# iND83213A register map
Vendor: Indiemicro; Series: Rugby; File version: 1.0
CPU: CM0 r0p1, selectable endian, no MPU, no FPU, 4 interrupt priority bits
Registers are 32-bit, read-write, no defined reset value unless marked. A register's access mark holds for its fields unless they carry their own. Offsets are from the block's base; [hi:lo] are bit positions; <NAME> marks a mode.

## IOCTRLA — I/O configuration and DFT pin control
Base 0x50012000; register names take the prefix IOCTRLA_
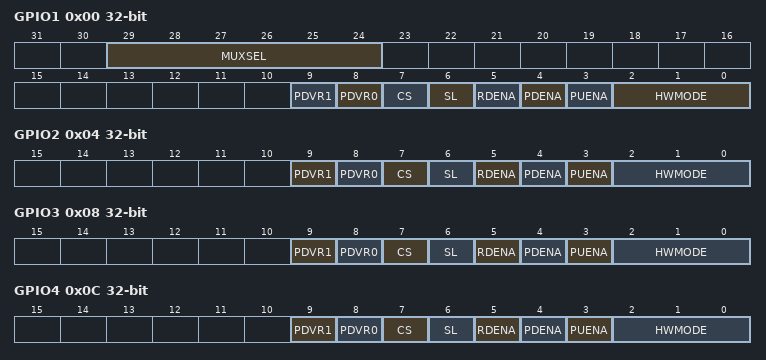
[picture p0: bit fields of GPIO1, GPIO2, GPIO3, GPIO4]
0x00 GPIO1 — GPIO Pin 1 Control
  [29:24] MUXSEL — Selects debug signal to be output on gpio1. 0x0: PMUA (Power Management Unit Asic) qacks[0] 0x1: PMUA (Power Management Unit Asic) daffodil[0] 0x2: PMUA (Power Management Unit Asic) snowflake[0] 0x3: CRGA (Clock Reset Generation Asic) lf_rc_clk 0x4: CRGA (Clock Reset Generation Asic) hf_rc_clk 0x5: CRGA (Clock Reset Generation Asic) lf_rc_sts 0x6: CRGA (Clock Reset Generation Asic) hf_rc_sts 0x7: CRGA (Clock Reset Generation Asic) clk_sys_gated 0x8: CRGA (Clock Reset Generation Asic) (a_por_n) 0x9: CRGA (Clock Reset Generation Asic) (bor_3v3_n) 0xa: CRGA (Clock Reset Generation Asic) (ovtemp_flag) 0xb: CRGA (Clock Reset Generation Asic) (bor_1v5_n) 0xc: CRGA (Clock Reset Generation Asic) (wdt_bark) 0xd: Reserved 0xe: ADC ctrl (Analog to Digital Converter Controller) adc_done 0xf: ADC ctrl (Analog to Digital Converter Controller) sar_dout 0x10: ADC ctrl (Analog to Digital Converter Controller) sar_smp_vcm 0x11: ADC ctrl (Analog to Digital Converter Controller) sar_div_clk 0x12: LINM Controller rxd 0x13: LINM Controller txd 0x14: LINS Controller rxd 0x15: LINS Controller txd 0x16: BOR CONTROL STATE MACHINE state[0] 0x17: BOR CONTROL STATE MACHINE state[1] 0x18: BOR CONTROL STATE MACHINE bor_bias_ena 0x19: BOR CONTROL STATE MACHINE bor_bias_ena_l 0x1a: BOR CONTROL STATE MACHINE pmua_bor_bias_ena 0x1b: BOR CONTROL STATE MACHINE hf_clk_allowed 0x1c: BOR CONTROL STATE MACHINE hf_active 0x1d: BOR CONTROL STATE MACHINE pmua_bor_arm_sync 0x1e: BATTERY VOLTAGE MONITOR raw output from vbat low comp 0x1f: BATTERY VOLTAGE MONITOR raw output from vbat high comp 0x20: BATTERY VOLTAGE MONITOR synchronised vbat low signal with polarity adjusted 0x21: BATTERY VOLTAGE MONITOR synchronised vbat high signal with polarity adjusted 0x22: BATTERY VOLTAGE MONITOR debounced synchronised vbat low signal 0x23: BATTERY VOLTAGE MONITOR debounced synchronised vbat high signal 0x24: BUCK dtb[0] 0x25: BUCK dtb[1] 0x26: Output of LINS 1st Stage Glitch Filter 0x27: Output of LINS 2nd Stage Glitch Filter 0x28: Output of LINS 3rd Stage Glitch Filter 0x29: Input of LINS 1st Stage Glitch Filter 0x2a: LINS PHY TXD 0x2b: Output of LINM 1st Stage Glitch Filter 0x2c: Output of LINM 2nd Stage Glitch Filter 0x2d: Output of LINM 3rd Stage Glitch Filter 0x2e: Input of LINM 1st Stage Glitch Filter 0x2f: LINM PHY TXD
  [9] PDVR1 — GPIO output drive strength MSB selector. GPIO output drive strength MSB selector. <table id="indie_table_table_regs"> <tbody><tr> <td> PDRV1 </td> <td> PDRV0 </td> <td> Output drive strength </td> </tr> <tr> <td> 0 </td> <td> 0 </td> <td> 4mA </td> </tr> <tr> <td> 0 </td> <td> 1 </td> <td> 8mA </td> </tr> <tr> <td> 1 </td> <td> 0 </td> <td> 12mA </td> </tr> <tr> <td> 1 </td> <td> 1 </td> <td> 16mA </td> </tr></tbody></table>
  [8] PDVR0 — GPIO output drive strength LSB selector. GPIO output drive strength LSB selector.
  [7] CS — input schmitt trigger enable. 0x0: Disable schmitt trigger 0x1: Enable schmitt trigger.
  [6] SL — slewrate ctrl. 0x0: Fast Slewrate on the GPIO 0x1: Slow Slewrate on the GPIO
  [5] RDENA — read enable. 0x0: Disable Read path on the GPIO 0x1: Enable Read path on the GPIO
  [4] PDENA — pulldown enable. 0x0: Disable 100K Ohm Pull Down 0x1: Enable 100K Ohm Pull Down
  [3] PUENA — pullup enable (active-low). 0x0: Enable 100K Ohm Pull Up 0x1: Disable 100K Ohm Pull Up
  [2:0] HWMODE — hardware mode. 0x0: GPA[0] Mode. 'GPIO Barium' reads and writes data to the GPIO. Output Enable is controlled by GPIO Barium via the direction bit. Read Enable, Pull-Up, and Pull-Down are controlled by GPIO register in IOCTRLA. 0x1: PWM[0] Mode. 'PWM Barium' writes data to the GPIO. 0x2: Testmux Mode. 'Digital Testmux' writes data to the GPIO. DEBUG Access must be enabled in the system control block to allow testmux outputs. 0x3: LINM controller RXD Input from GPIO(External PHY). 0x4: LINM Single wire mode, LINM PHY RXD/LINM PHY TXD, Open-drain output. 0x5: Output of LINS 3rd Stage Glitch Filter. 0x6: Output of LINM 3rd Stage Glitch Filter.
0x04 GPIO2 — GPIO Pin 2 Control
  [9] PDVR1 — GPIO output drive strength MSB selector. GPIO output drive strength MSB selector. <table id="indie_table_table_regs"> <tbody><tr> <td> PDRV1 </td> <td> PDRV0 </td> <td> Output drive strength </td> </tr> <tr> <td> 0 </td> <td> 0 </td> <td> 4mA </td> </tr> <tr> <td> 0 </td> <td> 1 </td> <td> 8mA </td> </tr> <tr> <td> 1 </td> <td> 0 </td> <td> 12mA </td> </tr> <tr> <td> 1 </td> <td> 1 </td> <td> 16mA </td> </tr></tbody></table>
  [8] PDVR0 — GPIO output drive strength LSB selector. GPIO output drive strength LSB selector.
  [7] CS — input schmitt trigger enable. 0x0: Disable schmitt trigger 0x1: Enable schmitt trigger.
  [6] SL — slewrate ctrl. 0x0: Fast Slewrate on the GPIO 0x1: Slow Slewrate on the GPIO
  [5] RDENA — read enable. 0x0: Disable Read path on the GPIO 0x1: Enable Read path on the GPIO
  [4] PDENA — pulldown enable. 0x0: Disable 100K Ohm Pull Down 0x1: Enable 100K Ohm Pull Down
  [3] PUENA — pullup enable (active-low). 0x0: Enable 100K Ohm Pull Up 0x1: Disable 100K Ohm Pull Up
  [2:0] HWMODE — hardware mode. 0x0: GPA[1] Mode. 'GPIO Barium' reads and writes data to the GPIO. Output Enable is controlled by GPIO Barium via the direction bit. Read Enable, Pull-Up, and Pull-Down are controlled by GPIO register in IOCTRLA. 0x1: PWM[1] Mode. 'PWM Barium' writes data to the GPIO. 0x2: Testmux Mode. GPIO input connects to LINS PHY TXD. DEBUG Access must be enabled in the system control block to allow testmux outputs. 0x3: LINM PHY TXD. 0x4: SPI Master Slave Select. 0x5: bor_3v3_n, BOR 3V3 reset. 0x6: bor_1v5_n, BOR 1V5 reset. 0x7: Input of LINS 1st Stage Glitch Filter.
0x08 GPIO3 — GPIO Pin 3 Control
  [9] PDVR1 — GPIO output drive strength MSB selector. GPIO output drive strength MSB selector. <table id="indie_table_table_regs"> <tbody><tr> <td> PDRV1 </td> <td> PDRV0 </td> <td> Output drive strength </td> </tr> <tr> <td> 0 </td> <td> 0 </td> <td> 4mA </td> </tr> <tr> <td> 0 </td> <td> 1 </td> <td> 8mA </td> </tr> <tr> <td> 1 </td> <td> 0 </td> <td> 12mA </td> </tr> <tr> <td> 1 </td> <td> 1 </td> <td> 16mA </td> </tr></tbody></table>
  [8] PDVR0 — GPIO output drive strength LSB selector. GPIO output drive strength LSB selector.
  [7] CS — input schmitt trigger enable. 0x0: Disable schmitt trigger 0x1: Enable schmitt trigger.
  [6] SL — slewrate ctrl. 0x0: Fast Slewrate on the GPIO 0x1: Slow Slewrate on the GPIO
  [5] RDENA — read enable. 0x0: Disable Read path on the GPIO 0x1: Enable Read path on the GPIO
  [4] PDENA — pulldown enable. 0x0: Disable 100K Ohm Pull Down 0x1: Enable 100K Ohm Pull Down
  [3] PUENA — pullup enable (active-low). 0x0: Enable 100K Ohm Pull Up 0x1: Disable 100K Ohm Pull Up
  [2:0] HWMODE — hardware mode. 0x0: GPA[2] Mode. 'GPIO Barium' reads and writes data to the GPIO. Output Enable is controlled by GPIO Barium via the direction bit. Read Enable, Pull-Up, and Pull-Down are controlled by GPIO register in IOCTRLA. 0x1: PWM[2] Mode. 'PWM Barium' writes data to the GPIO. 0x2: LINM controller RXD connects to GPIO for observe. 0x3: LINS controller RXD Input from GPIO(External PHY). 0x4: LINS Single wire mode, LINS PHY RXD/LINS PHY TXD, Open-drain output. 0x5: SPI Master Clock Out. 0x6: Output of LINS 1st Stage Glitch Filter. 0x7: Output of LINM 1st Stage Glitch Filter.
0x0C GPIO4 — GPIO Pin 4 Control
  [9] PDVR1 — GPIO output drive strength MSB selector. GPIO output drive strength MSB selector. <table id="indie_table_table_regs"> <tbody><tr> <td> PDRV1 </td> <td> PDRV0 </td> <td> Output drive strength </td> </tr> <tr> <td> 0 </td> <td> 0 </td> <td> 4mA </td> </tr> <tr> <td> 0 </td> <td> 1 </td> <td> 8mA </td> </tr> <tr> <td> 1 </td> <td> 0 </td> <td> 12mA </td> </tr> <tr> <td> 1 </td> <td> 1 </td> <td> 16mA </td> </tr></tbody></table>
  [8] PDVR0 — GPIO output drive strength LSB selector. GPIO output drive strength LSB selector.
  [7] CS — input schmitt trigger enable. 0x0: Disable schmitt trigger 0x1: Enable schmitt trigger.
  [6] SL — slewrate ctrl. 0x0: Fast Slewrate on the GPIO 0x1: Slow Slewrate on the GPIO
  [5] RDENA — read enable. 0x0: Disable Read path on the GPIO 0x1: Enable Read path on the GPIO
  [4] PDENA — pulldown enable. 0x0: Disable 100K Ohm Pull Down 0x1: Enable 100K Ohm Pull Down
  [3] PUENA — pullup enable (active-low). 0x0: Enable 100K Ohm Pull Up 0x1: Disable 100K Ohm Pull Up
  [2:0] HWMODE — hardware mode. 0x0: GPA[3] Mode. 'GPIO Barium' reads and writes data to the GPIO. Output Enable is controlled by GPIO Barium via the direction bit. Read Enable, Pull-Up, and Pull-Down are controlled by GPIO register in IOCTRLA. 0x1: PWM[3] Mode. 'PWM Barium' writes data to the GPIO. 0x2: UART RXD Input from GPIO 0x3: UART Single Wire Mode 0x4: SPI Master MOSI 0x5: Testmux Mode. GPIO input connects to LINM PHY TXD. 0x6: Output of LINS 2nd Stage Glitch Filter. 0x7: Output of LINM 2nd Stage Glitch Filter.
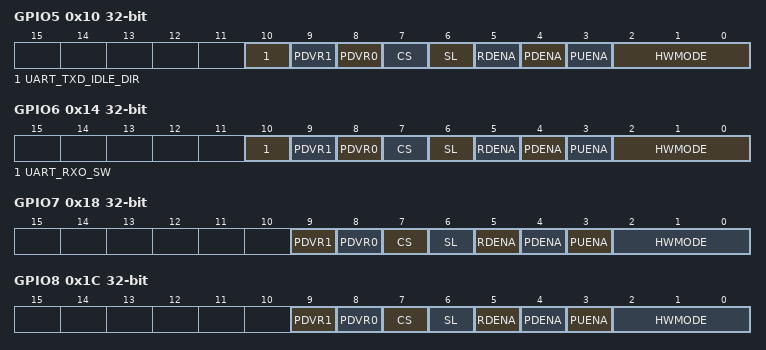
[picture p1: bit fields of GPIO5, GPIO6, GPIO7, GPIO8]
0x10 GPIO5 — GPIO Pin 5 Control
  [10] UART_TXD_IDLE_DIR — Control the direction of PAD for UART TXD Idle. 0x0: Hold the UART TXD Pad to output when TXD is idle, 0x1: Switch the TXD Pad to input When TXD is idle.
  [9] PDVR1 — GPIO output drive strength MSB selector. GPIO output drive strength MSB selector. <table id="indie_table_table_regs"> <tbody><tr> <td> PDRV1 </td> <td> PDRV0 </td> <td> Output drive strength </td> </tr> <tr> <td> 0 </td> <td> 0 </td> <td> 4mA </td> </tr> <tr> <td> 0 </td> <td> 1 </td> <td> 8mA </td> </tr> <tr> <td> 1 </td> <td> 0 </td> <td> 12mA </td> </tr> <tr> <td> 1 </td> <td> 1 </td> <td> 16mA </td> </tr></tbody></table>
  [8] PDVR0 — GPIO output drive strength LSB selector. GPIO output drive strength LSB selector.
  [7] CS — input schmitt trigger enable. 0x0: Disable schmitt trigger 0x1: Enable schmitt trigger.
  [6] SL — slewrate ctrl. 0x0: Fast Slewrate on the GPIO 0x1: Slow Slewrate on the GPIO
  [5] RDENA — read enable. 0x0: Disable Read path on the GPIO 0x1: Enable Read path on the GPIO
  [4] PDENA — pulldown enable. 0x0: Disable 100K Ohm Pull Down 0x1: Enable 100K Ohm Pull Down
  [3] PUENA — pullup enable (active-low). 0x0: Enable 100K Ohm Pull Up 0x1: Disable 100K Ohm Pull Up
  [2:0] HWMODE — hardware mode. 0x0: GPA[4] Mode. 'GPIO Barium' reads and writes data to the GPIO. Output Enable is controlled by GPIO Barium via the direction bit. Read Enable, Pull-Up, and Pull-Down are controlled by GPIO register in IOCTRLA. 0x1: PWM[4] Mode. 'PWM Barium' writes data to the GPIO. 0x2: UART TXD Output to GPIO 0x3: LINS PHY TXD Output to GPIO. 0x4: SPI Master MISO. 0x5: Input of LINM 1st Stage Glitch Filter. 0x6: Output of LINS 1st Stage Glitch Filter. 0x7: Output of LINM 1st Stage Glitch Filter.
0x14 GPIO6 — GPIO Pin 6 Control
  [10] UART_RXO_SW — UART RX output Switch. 0x0: Bypass UART RXD 0x1: Force UART RXD output to Reset Value-'1'
  [9] PDVR1 — GPIO output drive strength MSB selector. GPIO output drive strength MSB selector. <table id="indie_table_table_regs"> <tbody><tr> <td> PDRV1 </td> <td> PDRV0 </td> <td> Output drive strength </td> </tr> <tr> <td> 0 </td> <td> 0 </td> <td> 4mA </td> </tr> <tr> <td> 0 </td> <td> 1 </td> <td> 8mA </td> </tr> <tr> <td> 1 </td> <td> 0 </td> <td> 12mA </td> </tr> <tr> <td> 1 </td> <td> 1 </td> <td> 16mA </td> </tr></tbody></table>
  [8] PDVR0 — GPIO output drive strength LSB selector. GPIO output drive strength LSB selector.
  [7] CS — input schmitt trigger enable. 0x0: Disable schmitt trigger 0x1: Enable schmitt trigger.
  [6] SL — slewrate ctrl. 0x0: Fast Slewrate on the GPIO 0x1: Slow Slewrate on the GPIO
  [5] RDENA — read enable. 0x0: Disable Read path on the GPIO 0x1: Enable Read path on the GPIO
  [4] PDENA — pulldown enable. 0x0: Disable 100K Ohm Pull Down 0x1: Enable 100K Ohm Pull Down
  [3] PUENA — pullup enable (active-low). 0x0: Enable 100K Ohm Pull Up 0x1: Disable 100K Ohm Pull Up
  [2:0] HWMODE — hardware mode. 0x0: GPA[5] Mode. 'GPIO Barium' reads and writes data to the GPIO. Output Enable is controlled by GPIO Barium via the direction bit. Read Enable, Pull-Up, and Pull-Down are controlled by GPIO register in IOCTRLA. 0x1: PWM[1] Mode. 'PWM Barium' writes data to the GPIO. 0x2: Testmux Mode. Output of LINS 3rd Stage Glitch Filter. 0x3: LINM controller txd or txd_timeout_dominant to GPIO. 0x4: SPI Master MISO. 0x5: UART RXD Output to GPIO. 0x6: Output of LINS 2nd Stage Glitch Filter. 0x7: Output of LINM 2nd Stage Glitch Filter.
0x18 GPIO7 — GPIO Pin 7 Control
  [9] PDVR1 — GPIO output drive strength MSB selector. GPIO output drive strength MSB selector. <table id="indie_table_table_regs"> <tbody><tr> <td> PDRV1 </td> <td> PDRV0 </td> <td> Output drive strength </td> </tr> <tr> <td> 0 </td> <td> 0 </td> <td> 4mA </td> </tr> <tr> <td> 0 </td> <td> 1 </td> <td> 8mA </td> </tr> <tr> <td> 1 </td> <td> 0 </td> <td> 12mA </td> </tr> <tr> <td> 1 </td> <td> 1 </td> <td> 16mA </td> </tr></tbody></table>
  [8] PDVR0 — GPIO output drive strength LSB selector. GPIO output drive strength LSB selector.
  [7] CS — input schmitt trigger enable. 0x0: Disable schmitt trigger 0x1: Enable schmitt trigger.
  [6] SL — slewrate ctrl. 0x0: Fast Slewrate on the GPIO 0x1: Slow Slewrate on the GPIO
  [5] RDENA — read enable. 0x0: Disable Read path on the GPIO 0x1: Enable Read path on the GPIO
  [4] PDENA — pulldown enable. 0x0: Disable 100K Ohm Pull Down 0x1: Enable 100K Ohm Pull Down
  [3] PUENA — pullup enable (active-low). 0x0: Enable 100K Ohm Pull Up 0x1: Disable 100K Ohm Pull Up
  [2:0] HWMODE — hardware mode. 0x0: GPA[6] Mode. 'GPIO Barium' reads and writes data to the GPIO. Output Enable is controlled by GPIO Barium via the direction bit. Read Enable, Pull-Up, and Pull-Down are controlled by GPIO register in IOCTRLA. 0x1: PWM[2] Mode. 'PWM Barium' writes data to the GPIO. 0x2: Testmux Mode. Output of LINM 3rd Stage Glitch Filter. 0x3: LINS RXD Input from GPIO(External PHY). 0x4: LINS Single wire mode, LINS PHY RXD/LINS PHY TXD, Open-drain output. 0x5: SPI Master Clock Out. 0x6: UART TXD Input from GPIO. 0x7: Input of LINM 1st Stage Glitch Filter.
0x1C GPIO8 — GPIO Pin 8 Control
  [9] PDVR1 — GPIO output drive strength MSB selector. GPIO output drive strength MSB selector. <table id="indie_table_table_regs"> <tbody><tr> <td> PDRV1 </td> <td> PDRV0 </td> <td> Output drive strength </td> </tr> <tr> <td> 0 </td> <td> 0 </td> <td> 4mA </td> </tr> <tr> <td> 0 </td> <td> 1 </td> <td> 8mA </td> </tr> <tr> <td> 1 </td> <td> 0 </td> <td> 12mA </td> </tr> <tr> <td> 1 </td> <td> 1 </td> <td> 16mA </td> </tr></tbody></table>
  [8] PDVR0 — GPIO output drive strength LSB selector. GPIO output drive strength LSB selector.
  [7] CS — input schmitt trigger enable. 0x0: Disable schmitt trigger 0x1: Enable schmitt trigger.
  [6] SL — slewrate ctrl. 0x0: Fast Slewrate on the GPIO 0x1: Slow Slewrate on the GPIO
  [5] RDENA — read enable. 0x0: Disable Read path on the GPIO 0x1: Enable Read path on the GPIO
  [4] PDENA — pulldown enable. 0x0: Disable 100K Ohm Pull Down 0x1: Enable 100K Ohm Pull Down
  [3] PUENA — pullup enable (active-low). 0x0: Enable 100K Ohm Pull Up 0x1: Disable 100K Ohm Pull Up
  [2:0] HWMODE — hardware mode. 0x0: GPA[7] Mode. 'GPIO Barium' reads and writes data to the GPIO. Output Enable is controlled by GPIO Barium via the direction bit. Read Enable, Pull-Up, and Pull-Down are controlled by GPIO register in IOCTRLA. 0x1: PWM[3] Mode. 'PWM Barium' writes data to the GPIO. 0x2: UART RXD Input from GPIO 0x3: UART Single Wire Mode 0x4: SPI Master MOSI 0x5: Output of LINS 2nd Stage Glitch Filter. 0x6: Output of LINM 2nd Stage Glitch Filter.
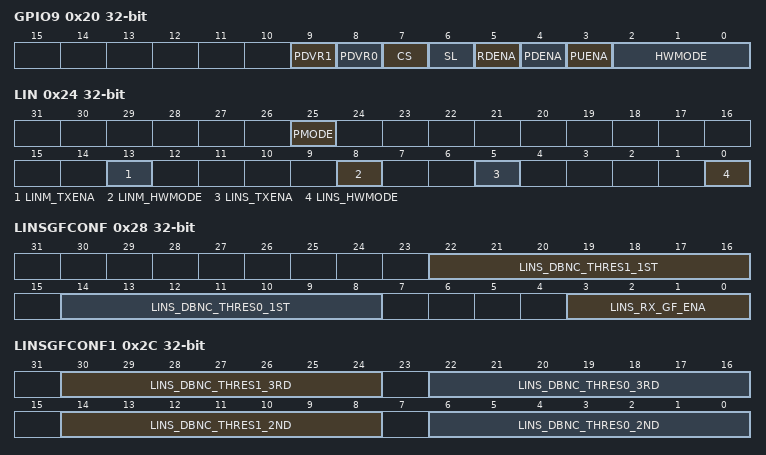
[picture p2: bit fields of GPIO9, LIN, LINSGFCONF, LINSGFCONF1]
0x20 GPIO9 — GPIO Pin 9 Control
  [9] PDVR1 — GPIO output drive strength MSB selector. GPIO output drive strength MSB selector. <table id="indie_table_table_regs"> <tbody><tr> <td> PDRV1 </td> <td> PDRV0 </td> <td> Output drive strength </td> </tr> <tr> <td> 0 </td> <td> 0 </td> <td> 4mA </td> </tr> <tr> <td> 0 </td> <td> 1 </td> <td> 8mA </td> </tr> <tr> <td> 1 </td> <td> 0 </td> <td> 12mA </td> </tr> <tr> <td> 1 </td> <td> 1 </td> <td> 16mA </td> </tr></tbody></table>
  [8] PDVR0 — GPIO output drive strength LSB selector. GPIO output drive strength LSB selector.
  [7] CS — input schmitt trigger enable. 0x0: Disable schmitt trigger 0x1: Enable schmitt trigger.
  [6] SL — slewrate ctrl. 0x0: Fast Slewrate on the GPIO 0x1: Slow Slewrate on the GPIO
  [5] RDENA — read enable. 0x0: Disable Read path on the GPIO 0x1: Enable Read path on the GPIO
  [4] PDENA — pulldown enable. 0x0: Disable 100K Ohm Pull Down 0x1: Enable 100K Ohm Pull Down
  [3] PUENA — pullup enable (active-low). 0x0: Enable 100K Ohm Pull Up 0x1: Disable 100K Ohm Pull Up
  [2:0] HWMODE — hardware mode. 0x0: GPB[0] Mode. 'GPIO Barium' reads and writes data to the GPIO. Output Enable is controlled by GPIO Barium via the direction bit. Read Enable, Pull-Up, and Pull-Down are controlled by GPIO register in IOCTRLA. 0x1: PWM[4] Mode. 'PWM Barium' writes data to the GPIO. 0x2: UART TXD Output to GPIO 0x3: LINS PHY TXD Output to GPIO. 0x4: SPI Master Slave Select. 0x5: Input of LINS 1st Stage Glitch Filter. 0x6: Input of LINM 1st Stage Glitch Filter.
0x24 LIN — LIN Pin Control
  [25] PMODE — LIN Power Mode. Control LINS/LINM power state in hibernate mode. 0x0: Regardless of the related enable bits, LIN TX analog parts will be shut-down in hibernate mode, unless any LIN dominant signal is detected. 0x1: LIN TX analog parts are still controlled by theirs corresponding enable bits.
  [13] LINM_TXENA — LIN transmit enable.
  [8] LINM_HWMODE — LIN Master hardware mode. 0x0: Hardware Mode Disabled. GPIO Barium Peripheral GPB[2] writes/reads the LIN I/O pin. 0x1: Hardware Mode Enabled. LIN peripheral writes/read the LIN I/O pin.
  [5] LINS_TXENA — LIN transmit enable.
  [0] LINS_HWMODE — LIN Slave hardware mode. 0x0: Hardware Mode Disabled. GPIO Barium Peripheral GPB[1] writes/reads the LIN I/O pin. 0x1: Hardware Mode Enabled. LIN peripheral writes/reads the LIN I/O pin.
0x28 LINSGFCONF — LINS Glitch Filter Configuration in active mode
  [22:16] LINS_DBNC_THRES1_1ST — 1st Stage LINS Debounce Threshold for 0 to 1. 1st Stage LINS Debounce Threshold for 0 to 1, detect '1' width of (T_clksys*resetvalue = 62.5ns*0 = 0[us].
  [14:8] LINS_DBNC_THRES0_1ST — 1st Stage LINS Debounce Threshold for 1 to 0. 1st Stage LINS Debounce Threshold for 1 to 0, detect '0' width of (T_clksys*resetvalue = 62.5ns*8 = 0.5[us].
  [3:0] LINS_RX_GF_ENA — LINS RXD Glitch Filter enables. bit-0: Enable LINS Glitch Filter 1st stage; bit-1: Enable LINS Glitch Filter 2nd stage; bit-2: Enable LINS Glitch Filter 3rd stage; bit-3: Enable LINS Glitch Filter for Sleep Mode NOTE: The write operation of this register takes effect by configuring SYSCTRLA_SFRS->TRIM_ACCESS_KEY.TRIM_ACCESS_KEY, FILT_ACCESS.FILT_UNLOCK
0x2C LINSGFCONF1 — LINS Glitch Filter Configuration in active mode
  [30:24] LINS_DBNC_THRES1_3RD — 3rd Stage LINS Debounce Threshold for 0 to 1. 3rd Stage LINS Debounce Threshold for 0 to 1, detect '1' width of (T_clksys*resetvalue = 62.5ns*40 = 2.5[us].
  [22:16] LINS_DBNC_THRES0_3RD — 3rd Stage LINS Debounce Threshold for 1 to 0. 3rd Stage LINS Debounce Threshold for 1 to 0, detect '0' width of (T_clksys*resetvalue = 62.5ns*40 = 2.5[us].
  [14:8] LINS_DBNC_THRES1_2ND — 2nd Stage LINS Debounce Threshold for 0 to 1. 2nd Stage LINS Debounce Threshold for 0 to 1, detect '1' width of (T_clksys*resetvalue = 62.5ns*32 = 2[us].
  [6:0] LINS_DBNC_THRES0_2ND — 2nd Stage LINS Debounce Threshold for 1 to 0. 2nd Stage LINS Debounce Threshold for 1 to 0, detect '0' width of (T_clksys*resetvalue = 62.5ns*16 = 1[us].
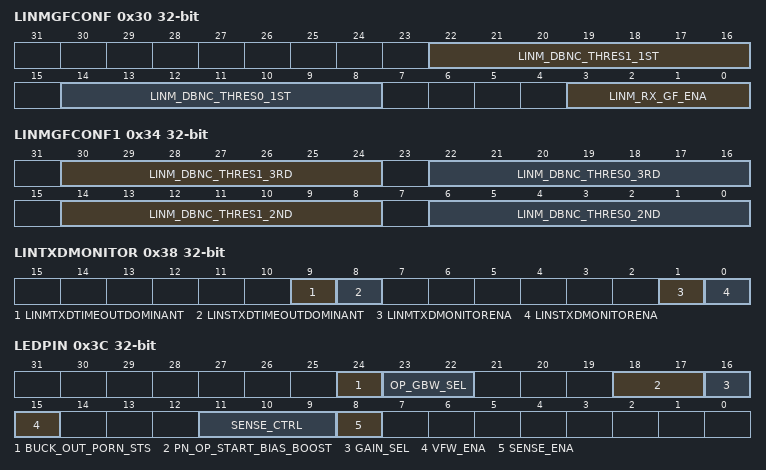
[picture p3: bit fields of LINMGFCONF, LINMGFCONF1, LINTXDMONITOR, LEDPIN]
0x30 LINMGFCONF — LINM Glitch Filter Configuration in active mode
  [22:16] LINM_DBNC_THRES1_1ST — LINM Debounce Threshold for 0 to 1. 1st Stage LINM Debounce Threshold for 0 to 1, detect '1' width of (T_clksys*resetvalue = 62.5ns*0 = 0[us].
  [14:8] LINM_DBNC_THRES0_1ST — LINM Debounce Threshold for 1 to 0. 1st Stage LINM Debounce Threshold for 1 to 0, detect '0' width of (T_clksys*resetvalue = 62.5ns*8 = 0.5[us].
  [3:0] LINM_RX_GF_ENA — LINM RXD Glitch Filter enables. bit-0: Enable LINM Glitch Filter 1st stage; bit-1: Enable LINM Glitch Filter 2nd stage; bit-2: Enable LINM Glitch Filter 3rd stage; bit-3: Enable LINM Glitch Filter for Sleep Mode NOTE: The write operation of this register takes effect by configuring SYSCTRLA_SFRS->TRIM_ACCESS_KEY.TRIM_ACCESS_KEY, FILT_ACCESS.FILT_UNLOCK
0x34 LINMGFCONF1 — LINM Glitch Filter Configuration in active mode
  [30:24] LINM_DBNC_THRES1_3RD — 3rd Stage LINM Debounce Threshold for 0 to 1. 3rd Stage LINM Debounce Threshold for 0 to 1, detect '1' width of (T_clksys*resetvalue = 62.5ns*40 = 2.5[us].
  [22:16] LINM_DBNC_THRES0_3RD — 3rd Stage LINM Debounce Threshold for 1 to 0. 3rd Stage LINM Debounce Threshold for 1 to 0, detect '0' width of (T_clksys*resetvalue = 62.5ns*40 = 2.5[us].
  [14:8] LINM_DBNC_THRES1_2ND — 2nd Stage LINM Debounce Threshold for 0 to 1. 2nd Stage LINM Debounce Threshold for 0 to 1, detect '1' width of (T_clksys*resetvalue = 62.5ns*32 = 2[us].
  [6:0] LINM_DBNC_THRES0_2ND — 2nd Stage LINM Debounce Threshold for 1 to 0. 2nd Stage LINM Debounce Threshold for 1 to 0, detect '0' width of (T_clksys*resetvalue = 62.5ns*16 = 1[us].
0x38 LINTXDMONITOR — LIN TXD Dominant Timeout
  [9] LINMTXDTIMEOUTDOMINANT ro — Tx Dominant Timeout. The bit is set by LINM TxD monitor if LINM's TxD is stuck at dominant output for 64ms. A dominant to recessive transition of the TxD will clear this bit. LIN's TX will be disabled automatically when this bit is set.
  [8] LINSTXDTIMEOUTDOMINANT ro — Tx Dominant Timeout. The bit is set by LINS TxD monitor if LINS's TxD is stuck at dominant output for 64ms. A dominant to recessive transition of the TxD will clear this bit. LIN's TX will be disabled automatically when this bit is set.
  [1] LINMTXDMONITORENA — LINM TxD Monitor enable.
  [0] LINSTXDMONITORENA — LINS TxD Monitor enable.
0x3C LEDPIN — LED Pin Control
  [24] BUCK_OUT_PORN_STS ro — BUCK ouput volatage POR flag. 0: BUCKOUT < 2.1V(typ) 1: BUCKOUT > 2.3V
  [23:22] OP_GBW_SEL — LED SENSE OP GBW SEL. PN detect fully differential Op GBW choose 00: 3M 01: 5M 10: 8M 11: 10M
  [18:17] PN_OP_START_BIAS_BOOST — PN OP START BIAS BOOST. PN diff OP start bias current 00: 1uA 01: 2uA 10: 3uA 11: 4uA
  [16] GAIN_SEL — LED Sense AFE gain select. V_ADC = (vbat-vled)*GAIN , where V_ADC is voltage to ADC LED channle, and GAIN is selected by GAIN_SEL as following: 0x0: GAIN = 2/5 0x1: GAIN = 1/5
  [15] VFW_ENA — LED Forward Voltage Current Enable. Set to enable the independent LED VFW current source(maximum=5mA). When ADC CH2 measurement is active, the LED channel selected by CH2_SEL will be driven by LED_VFW current source.
  [11:9] SENSE_CTRL — LED. LED Sense Control bits for override control/debug.
  [8] SENSE_ENA — LED Forward Voltage Sense Enable. Set to enable LED forward voltage sense module. After setting this bit, it's recommended to wait ~40us before ADC conversion for LED_SENSE to settle down.
0x40 LEDHWMODE
  [23:0] HWMODE — LED hardware mode. LED Hardware Mode Enable. Each bit controls the corresponding LED Channel respectively. 0x0: Hardware Mode Disabled. LED_DATA register drives the LED Data Output pin. Read is not available on this pin. 0x1: Hardware Mode Enabled. PWM_BARIUM peripheral drives the LED Data Output pin. Read is not available on this pin.
0x44 LEDDATA — LED Data Out
  [23:0] LEDDATA — LED Data Out. When the LED hardware mode is disabled, then the data in this register bit is used to drive the LED driver. Each bit controls the corresonding LED Channel respectively.
0x48 LEDPUENA — LED Data Out
  [23:0] LEDPUENA — LED Pullup Enable. Set to enable LED Pullup when no LED current source is connected.
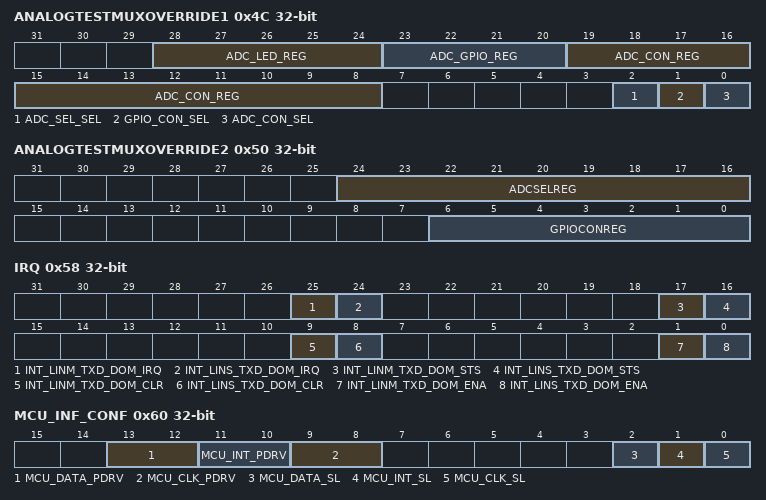
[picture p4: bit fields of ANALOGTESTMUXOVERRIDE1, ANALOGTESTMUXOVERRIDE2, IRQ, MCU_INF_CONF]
0x4C ANALOGTESTMUXOVERRIDE1
  [28:24] ADC_LED_REG — Select which channel of LED forward voltage to ADC by firmware. Control which LED channel is selected when the ADC_CON_SEL/ADC_CON_REG[11] are set.
  [23:20] ADC_GPIO_REG — Select which GPIO forward voltage to ADC by firmware. Control which GPIO channel is selected when the ADC_CON_SEL/ADC_CON_REG[9] are set. 0x0: Select GPIO6 0x1: Select GPIO7 0x2: Select GPIO8 0x3: Select GPIO1 0x4: Select GPIO2 0x5: Select GPIO3 0x6: Select GPIO4 0x7: Select GPIO5 0x8: Select GPIO9
  [19:8] ADC_CON_REG — Firmware Debug Value. Contains the output value when the ADC_CON_SEL firmware select bit is set. 0x1: Select All shot to adc_ref(2.4V) for adc channel offset K 0x2: Select adc_vinp= adc_refp, adc_vinn= vref_gnd 0x4: Select adc_vinp= vref_gnd, adc_vinn= adc_refp 0x8: Select GPIO6(adc_vinp)/GPIO7(adc_vinn) to ADC 0x10: Select Tempsensor to ADC 0x20: Select VDD1.5v to ADC 0x40: Select VDD3.3v to ADC 0x80: Select VDD5.0v(1/4) to ADC 0x100: Select Accurate VBAT to ADC 0x200: Select GPIO1~9(determined by CH4_SEL in ADC_CTRL) to ADC 0x400: Select BUCK 5V(1/4) to ADC 0x800: Select LED0~23 Forward Voltage to ADC
  [2] ADC_SEL_SEL — Hardware/Firmware Select NOTE:The write operation of this field register takes effect by configuring 'SYSCTRLA_SFRS->DEBUG_ACCESS_KEY.DEBUG_ACCESS_KEY = 0x05'. 0x0: Hardware Controlled. 0x1: ADC_SEL_REG controls output.
  [1] GPIO_CON_SEL — Hardware/Firmware Select NOTE:The write operation of this field register takes effect by configuring 'SYSCTRLA_SFRS->DEBUG_ACCESS_KEY.DEBUG_ACCESS_KEY = 0x05'. 0x0: Hardware Controlled. 0x1: GPIO_CON_REG controls output.
  [0] ADC_CON_SEL — Hardware/Firmware Select NOTE:The write operation of this field register takes effect by configuring 'SYSCTRLA_SFRS->DEBUG_ACCESS_KEY.DEBUG_ACCESS_KEY = 0x05'. 0x0: Hardware Controlled. 0x1: ADC_CON_REG controls output.
0x50 ANALOGTESTMUXOVERRIDE2
  [24:16] ADCSELREG — Firmware Debug Value. Need to be configured with gpio_con_reg to enable gpio analog output to ADC. 0x1: Enable GPIO1 analog connection 0x2: Enable GPIO2 analog connection 0x4: Enable GPIO3 analog connection 0x8: Enable GPIO4 analog connection 0x10: Enable GPIO5 analog connection 0x20: Enable GPIO6 analog connection 0x40: Enable GPIO7 analog connection 0x80: Enable GPIO8 analog connection 0x100: Enable GPIO9 analog connection
  [6:0] GPIOCONREG — Firmware Debug Value. GPIO1~9 test MUX select. ADC_SEL_SEL/ADC_SEL_REG need to be configured at the same time to enable required GPIO connection. 0x1: Select VDD 3.3V digital supply to GPIO6, mutually exclusive with HVBUCK_ATB01. 0x2: Select 1.5v MCU supply to GPIO6, mutually exclusive with HVBUCK_ATB01. 0x4: Select VDD_PRE5V/4 to GPIO6, mutually exclusive with HVBUCK_ATB01. 0x8: Select BUCK_5V/4 to GPIO6, mutually exclusive with HVBUCK_ATB01. 0x10: Select ADC_REFP to GPIO7, mutually exclusive with HVBUCK_ATB02 and PMU_ATB. 0x20: Select ADC_INP to GPIO7, mutually exclusive with HVBUCK_ATB02 and PMU_ATB. 0x40: Select ADC_INN to GPIO8, mutually exclusive with PMU_ATB1, mutually exclusive with lin_ibg1up_tp.
0x54 ANALOGTESTMUXOVERRIDE3
  [23:0] LEDSEL — LED test analog channel select, one hot code NOTE:exclusive with DFT_MODE_ENA_LED.
0x58 IRQ — IOCTRLA LINS/LINM TXD Dominant Monitor interrupts
  [25] INT_LINM_TXD_DOM_IRQ ro — LINM TXD Dominant Monitor interrupt active.
  [24] INT_LINS_TXD_DOM_IRQ ro — LINS TXD Dominant Monitor interrupt active.
  [17] INT_LINM_TXD_DOM_STS ro — LINM TXD Dominant Monitor interrupt status.
  [16] INT_LINS_TXD_DOM_STS ro — LINS TXD Dominant Monitor interrupt status.
  [9] INT_LINM_TXD_DOM_CLR wo — LINM TXD Dominant Monitor interrupt clear. Autoclear: includes a synchronous reset signal which clears the register on the cycle following write.
  [8] INT_LINS_TXD_DOM_CLR wo — LINS TXD Dominant Monitor interrupt clear. Autoclear: includes a synchronous reset signal which clears the register on the cycle following write.
  [1] INT_LINM_TXD_DOM_ENA — LINM TXD Dominant Monitor interrupt enable.
  [0] INT_LINS_TXD_DOM_ENA — LINS TXD Dominant Monitor interrupt enable.
0x5C FILT_ACCESS — Glitch Filter access key
  [31] FILT_UNLOCK — Set Only bit. Write 1 to this bit to un-lock FILT_CODE bits.
0x60 MCU_INF_CONF — Mcu interface access config
  [13:12] MCU_DATA_PDRV — mcu data drive strength control: 0-4mA 1-8mA 2-12mA 3-16mA
  [11:10] MCU_INT_PDRV — mcu int drive strength control: 0-4mA 1-8mA 2-12mA 3-16mA
  [9:8] MCU_CLK_PDRV — mcu clock drive strength control: 0-4mA 1-8mA 2-12mA 3-16mA
  [2] MCU_DATA_SL — mcu data slew rate control: 0-fast 1-slow
  [1] MCU_INT_SL — mcu int slew rate control: 0-fast 1-slow
  [0] MCU_CLK_SL — mcu clock slew rate control: 0-fast 1-slow
